VERSION ""

NS_ :

BS_:

BU_: VCM

BO_ 2364540158 EEC1: 8 Vector__XXX
 SG_ EngineSpeed : 24|16@1+ (0.125,0) [0|8031.875] "rpm" Vector__XXX

BO_ 2566844926 CCVS1: 8 Vector__XXX
 SG_ WheelBasedVehicleSpeed : 8|16@1+ (0.00390625,0) [0|250.996] "km/h" Vector__XXX

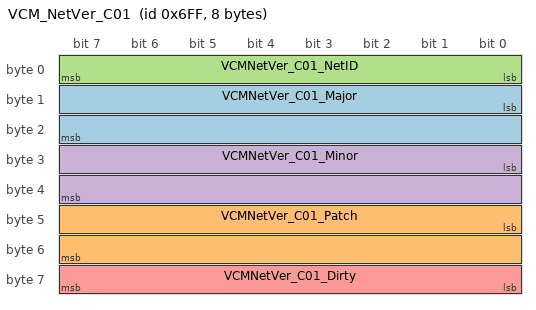
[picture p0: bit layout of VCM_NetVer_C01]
BO_ 1791 VCM_NetVer_C01: 8 VCM
 SG_ VCMNetVer_C01_Major : 8|16@1+ (1,0) [0|65535] "Not Applicable" Vector__XXX
 SG_ VCMNetVer_C01_Patch : 40|16@1+ (1,0) [0|65535] "Not Applicable" Vector__XXX
 SG_ VCMNetVer_C01_NetID : 0|8@1+ (1,0) [0|255] "NotApplicable" Vector__XXX
 SG_ VCMNetVer_C01_Minor : 24|16@1+ (1,0) [0|65535] "Not Applicable" Vector__XXX
 SG_ VCMNetVer_C01_Dirty : 56|8@1+ (1,0) [0|255] "NotApplicable" Vector__XXX

CM_ BO_ 2364540158 "Electronic Engine Controller 1";
CM_ SG_ 2364540158 EngineSpeed "Actual engine speed which is calculated over a minimum crankshaft angle of 720 degrees divided by the number of cylinders.…";
CM_ BO_ 2566844926 "Cruise Control/Vehicle Speed 1";
CM_ SG_ 2566844926 WheelBasedVehicleSpeed "Wheel-Based Vehicle Speed: Speed of the vehicle as calculated from wheel or tailshaft speed.";
CM_ BO_ 1791 "Version stuff";
CM_ SG_ 1791 VCMNetVer_C01_Major "Version stuff";
CM_ SG_ 1791 VCMNetVer_C01_Patch "Version stuff";
CM_ SG_ 1791 VCMNetVer_C01_NetID "Version stuff";
CM_ SG_ 1791 VCMNetVer_C01_Minor "Version stuff";
CM_ SG_ 1791 VCMNetVer_C01_Dirty "Version stuff";
BA_DEF_ SG_  "SPN" INT 0 524287;
BA_DEF_ BO_  "VFrameFormat" ENUM  "StandardCAN","ExtendedCAN","reserved","J1939PG";
BA_DEF_ BO_  "GenMsgSendType" ENUM  "Cyclic","NotUsed","NotUsed","NotUsed","NotUsed","NotUsed","NotUsed","IfActive","NoMsgSendType","NotUsed";
BA_DEF_ BO_  "GenMsgCycleTime" INT 0 0;
BA_DEF_  "DatabaseVersion" STRING ;
BA_DEF_  "BusType" STRING ;
BA_DEF_  "ProtocolType" STRING ;
BA_DEF_  "DatabaseCompiler" STRING ;
BA_DEF_ SG_  "GenSigCycleTimeActive" INT 0 0;
BA_DEF_ SG_  "GenSigCycleTime" INT 0 0;
BA_DEF_ SG_  "GenSigStartValue" INT 0 0;
BA_DEF_ SG_  "GenSigSendType" ENUM  "Cyclic","OnWrite","OnWriteWithRepetition","OnChange","OnChangeWithRepetition","IfActive","IfActiveWithRepetition","NoSigSendType","NotUsed","NotUsed","NotUsed","NotUsed","NotUsed";

BA_DEF_DEF_  "SPN" 0;
BA_DEF_DEF_  "VFrameFormat" "J1939PG";
BA_DEF_DEF_  "DatabaseVersion" "";
BA_DEF_DEF_  "BusType" "";
BA_DEF_DEF_  "ProtocolType" "";
BA_DEF_DEF_  "DatabaseCompiler" "";
BA_DEF_DEF_  "GenMsgSendType" "Cyclic";
BA_DEF_DEF_  "GenMsgCycleTime" 0;
BA_DEF_DEF_  "GenSigCycleTimeActive" 0;
BA_DEF_DEF_  "GenSigCycleTime" 0;
BA_DEF_DEF_  "GenSigSendType" "Cyclic";
BA_DEF_DEF_  "GenSigStartValue" 0;

BA_ "ProtocolType" "J1939";
BA_ "BusType" "CAN";
BA_ "DatabaseCompiler" "CSS ELECTRONICS (WWW.CSSELECTRONICS.COM)";
BA_ "DatabaseVersion" "1.0.0";
BA_ "VFrameFormat" BO_ 1791 0;
BA_ "GenMsgCycleTime" BO_ 1791 1000;
BA_ "SPN" SG_ 2364540158 EngineSpeed 190;
BA_ "SPN" SG_ 2566844926 WheelBasedVehicleSpeed 84;
BA_ "GenSigCycleTime" SG_ 1791 VCMNetVer_C01_Major 100;
BA_ "GenSigCycleTimeActive" SG_ 1791 VCMNetVer_C01_Major 100;
BA_ "GenSigStartValue" SG_ 1791 VCMNetVer_C01_Major 2;
BA_ "GenSigCycleTime" SG_ 1791 VCMNetVer_C01_Patch 100;
BA_ "GenSigCycleTimeActive" SG_ 1791 VCMNetVer_C01_Patch 100;
BA_ "GenSigCycleTime" SG_ 1791 VCMNetVer_C01_NetID 100;
BA_ "GenSigCycleTimeActive" SG_ 1791 VCMNetVer_C01_NetID 100;
BA_ "GenSigStartValue" SG_ 1791 VCMNetVer_C01_NetID 1;
BA_ "GenSigCycleTime" SG_ 1791 VCMNetVer_C01_Minor 100;
BA_ "GenSigCycleTimeActive" SG_ 1791 VCMNetVer_C01_Minor 100;
BA_ "GenSigStartValue" SG_ 1791 VCMNetVer_C01_Minor 7;
BA_ "GenSigCycleTime" SG_ 1791 VCMNetVer_C01_Dirty 100;
BA_ "GenSigCycleTimeActive" SG_ 1791 VCMNetVer_C01_Dirty 100;
